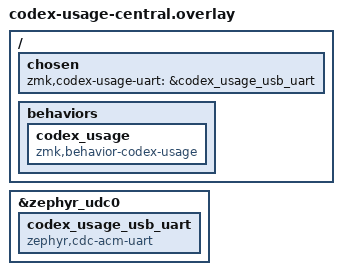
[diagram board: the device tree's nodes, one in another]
/* SPDX-License-Identifier: MIT */

/ {
    chosen {
        zmk,codex-usage-uart = &codex_usage_usb_uart;
    };

    behaviors {
        codex_usage: codex_usage {
            compatible = "zmk,behavior-codex-usage";
            #binding-cells = <2>;
        };
    };
};

&zephyr_udc0 {
    codex_usage_usb_uart: codex_usage_usb_uart {
        compatible = "zephyr,cdc-acm-uart";
    };
};
